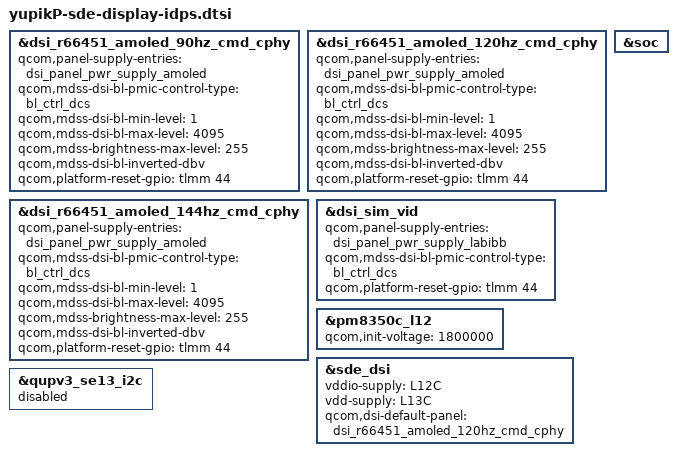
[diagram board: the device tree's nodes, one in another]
#include "yupik-sde-display.dtsi"

&dsi_r66451_amoled_90hz_cmd_cphy {
	qcom,panel-supply-entries = <&dsi_panel_pwr_supply_amoled>;
	qcom,mdss-dsi-bl-pmic-control-type = "bl_ctrl_dcs";
	qcom,mdss-dsi-bl-min-level = <1>;
	qcom,mdss-dsi-bl-max-level = <4095>;
	qcom,mdss-brightness-max-level = <255>;
	qcom,mdss-dsi-bl-inverted-dbv;
	qcom,platform-reset-gpio = <&tlmm 44 0>;
};

&dsi_r66451_amoled_120hz_cmd_cphy {
	qcom,panel-supply-entries = <&dsi_panel_pwr_supply_amoled>;
	qcom,mdss-dsi-bl-pmic-control-type = "bl_ctrl_dcs";
	qcom,mdss-dsi-bl-min-level = <1>;
	qcom,mdss-dsi-bl-max-level = <4095>;
	qcom,mdss-brightness-max-level = <255>;
	qcom,mdss-dsi-bl-inverted-dbv;
	qcom,platform-reset-gpio = <&tlmm 44 0>;
};

&dsi_r66451_amoled_144hz_cmd_cphy {
	qcom,panel-supply-entries = <&dsi_panel_pwr_supply_amoled>;
	qcom,mdss-dsi-bl-pmic-control-type = "bl_ctrl_dcs";
	qcom,mdss-dsi-bl-min-level = <1>;
	qcom,mdss-dsi-bl-max-level = <4095>;
	qcom,mdss-brightness-max-level = <255>;
	qcom,mdss-dsi-bl-inverted-dbv;
	qcom,platform-reset-gpio = <&tlmm 44 0>;
};

&dsi_sim_vid {
	qcom,panel-supply-entries = <&dsi_panel_pwr_supply_labibb>;
	qcom,mdss-dsi-bl-pmic-control-type = "bl_ctrl_dcs";
	qcom,platform-reset-gpio = <&tlmm 44 0>;
};

&soc {
};

&pm8350c_l12 {
	qcom,init-voltage = <1800000>;
};

&sde_dsi {
	vddio-supply = <&L12C>;
	vdd-supply = <&L13C>;
	qcom,dsi-default-panel = <&dsi_r66451_amoled_120hz_cmd_cphy>;
};

&qupv3_se13_i2c {
	status = "disabled";
};

/*
&qupv3_se13_spi {
        status = "ok";
        qcom,spi-touch-active = "focaltech,fts_ts";

        focaltech@0 {
		compatible = "focaltech,fts_ts";
		reg = <0x0>;
		spi-max-frequency = <6000000>;
		interrupt-parent = <&tlmm>;
		interrupts = <81 0x2008>;
		focaltech,reset-gpio = <&tlmm 105 0x00>;
		focaltech,irq-gpio = <&tlmm 81 0x2008>;
		focaltech,display-coords = <0 0 1080 2340>;
		focaltech,max-touch-number = <5>;
		focaltech,ic-type = <0x3658D488>;

		vdd-supply = <&L3C>;

		pinctrl-names = "pmx_ts_active", "pmx_ts_suspend","pmx_ts_release";
		pinctrl-0 = <&ts_active>;
		pinctrl-1 = <&ts_int_suspend &ts_reset_suspend>;
		pinctrl-2 = <&ts_release>;

		panel = <&dsi_r66451_amoled_144hz_cmd_cphy
			&dsi_r66451_amoled_120hz_cmd_cphy
			&dsi_r66451_amoled_90hz_cmd_cphy>;
	};
}; */
